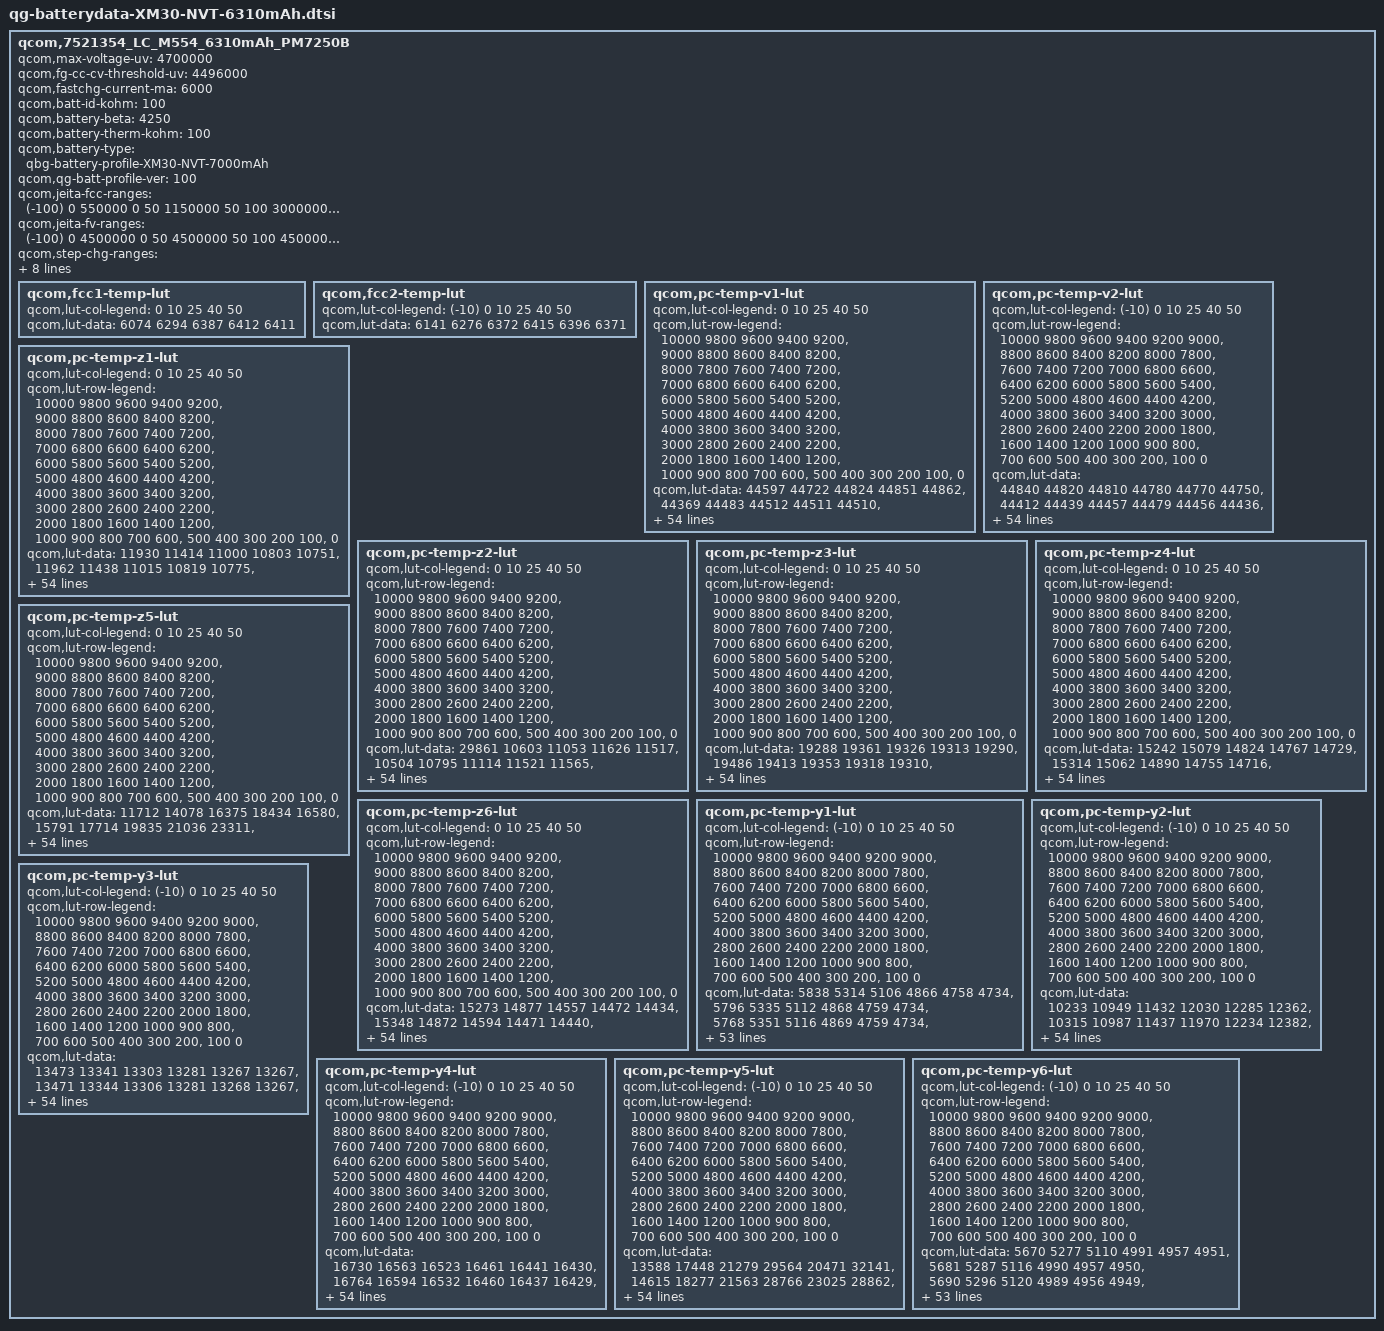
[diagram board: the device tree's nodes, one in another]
/* Copyright (c) 2018, The Linux Foundation. All rights reserved.
 *
 * This program is free software; you can redistribute it and/or modify
 * it under the terms of the GNU General Public License version 2 and
 * only version 2 as published by the Free Software Foundation.
 *
 * This program is distributed in the hope that it will be useful,
 * but WITHOUT ANY WARRANTY; without even the implied warranty of
 * MERCHANTABILITY or FITNESS FOR A PARTICULAR PURPOSE.  See the
 * GNU General Public License for more details.
 */

qcom,7521354_LC_M554_6310mAh_PM7250B {
    /* 7521354_LC_M554_6310mAh_PM7250B_averaged_MasterSlave_Dec20th2024 */
    qcom,max-voltage-uv = <4700000>;
    qcom,fg-cc-cv-threshold-uv = <4496000>;
    qcom,fastchg-current-ma = <6000>;
    qcom,batt-id-kohm = <100>;
    qcom,battery-beta = <4250>;
    qcom,battery-therm-kohm = <100>;
    qcom,battery-type = "qbg-battery-profile-XM30-NVT-7000mAh";
    qcom,qg-batt-profile-ver = <100>;

    qcom,jeita-fcc-ranges = <(-100)  0   550000
				0   50   1150000
				50  100  3000000
				100 150  3600000
				150 350  6000000
				350 450  6000000
				450 550  3000000>;
	qcom,jeita-fv-ranges = <(-100)   0   4500000
				0   50   4500000
				50  100  4500000
				100 150  4500000
				150 350  4560000
				350 480  4560000
				480 550  4100000>;
	qcom,step-chg-ranges = <3600000  4250000  6000000
				4250001  4500000  5400000
				4500001  4530000  4968000>;
	qcom,vbat-avg-based-step-chg;
	qcom,taper-fcc;

    /* COOL = 15 DegC, WARM = 45 DegC */
    qcom,jeita-soft-thresholds = <0x4621 0x20B8>;
    /* COLD = -10 DegC, HOT = 58 DegC */
    qcom,jeita-hard-thresholds = <0x6226 0x15F7>;
    /* COOL hys = 18 DegC, WARM hys = 42 DegC */
    qcom,jeita-soft-hys-thresholds = <0x4621 0x23C0>;

	qcom,jeita-soft-fcc-ua = <5400000 4500000>;
	qcom,jeita-soft-fv-uv = <4650000 4530000>;

	qcom,fcc1-temp-lut {
		qcom,lut-col-legend = <0 10 25 40 50>;
		qcom,lut-data = <6074 6294 6387 6412 6411>;
	};

	qcom,fcc2-temp-lut {
		qcom,lut-col-legend = <(-10) 0 10 25 40 50>;
		qcom,lut-data = <6141 6276 6372 6415 6396 6371>;
	};

	qcom,pc-temp-v1-lut {
		qcom,lut-col-legend = <0 10 25 40 50>;
		qcom,lut-row-legend = <10000 9800 9600 9400 9200>,
			<9000 8800 8600 8400 8200>,
			<8000 7800 7600 7400 7200>,
			<7000 6800 6600 6400 6200>,
			<6000 5800 5600 5400 5200>,
			<5000 4800 4600 4400 4200>,
			<4000 3800 3600 3400 3200>,
			<3000 2800 2600 2400 2200>,
			<2000 1800 1600 1400 1200>,
			<1000 900 800 700 600>,
			<500 400 300 200 100>,
			<0>;
		qcom,lut-data = <44597 44722 44824 44851 44862>,
			<44369 44483 44512 44511 44510>,
			<44158 44255 44286 44273 44268>,
			<43951 44041 44081 44064 44057>,
			<43737 43840 43872 43854 43848>,
			<43521 43632 43668 43651 43648>,
			<43297 43407 43449 43437 43437>,
			<43061 43172 43217 43206 43209>,
			<42820 42931 42976 42967 42974>,
			<42578 42679 42728 42720 42731>,
			<42334 42428 42474 42465 42483>,
			<42094 42178 42222 42214 42234>,
			<41860 41930 41970 41964 41984>,
			<41630 41690 41723 41718 41735>,
			<41408 41457 41484 41476 41493>,
			<41192 41230 41251 41238 41255>,
			<40984 41006 41026 41009 41025>,
			<40784 40791 40807 40788 40805>,
			<40592 40592 40599 40577 40593>,
			<40404 40407 40404 40379 40393>,
			<40229 40217 40212 40187 40200>,
			<40050 40010 39998 39979 39994>,
			<39825 39795 39765 39755 39777>,
			<39532 39568 39542 39533 39560>,
			<39285 39320 39330 39311 39334>,
			<39136 39121 39139 39105 39120>,
			<39023 38994 38989 38951 38961>,
			<38926 38891 38865 38827 38835>,
			<38846 38787 38754 38715 38720>,
			<38771 38685 38650 38608 38609>,
			<38692 38594 38556 38510 38507>,
			<38613 38512 38470 38420 38412>,
			<38542 38438 38393 38338 38325>,
			<38480 38375 38324 38264 38245>,
			<38425 38320 38266 38199 38175>,
			<38371 38269 38210 38138 38106>,
			<38321 38224 38155 38074 38031>,
			<38268 38178 38101 38009 37949>,
			<38213 38113 38032 37933 37863>,
			<38154 38023 37943 37841 37774>,
			<38073 37917 37838 37735 37673>,
			<37947 37793 37719 37615 37549>,
			<37800 37648 37578 37476 37405>,
			<37628 37470 37401 37306 37236>,
			<37475 37299 37230 37149 37085>,
			<37303 37162 37112 37044 36985>,
			<37233 37122 37083 37018 36959>,
			<37180 37090 37060 37000 36944>,
			<37137 37071 37038 36983 36927>,
			<37099 37034 36999 36939 36883>,
			<37055 36888 36784 36685 36636>,
			<36968 36451 36342 36231 36200>,
			<36638 35856 35743 35636 35622>,
			<36069 35028 34919 34815 34825>,
			<35083 33629 33627 33526 33604>,
			<30000 30000 30000 30000 30000>;
	};

	qcom,pc-temp-v2-lut {
		qcom,lut-col-legend = <(-10) 0 10 25 40 50>;
		qcom,lut-row-legend = <10000 9800 9600 9400 9200 9000>,
			<8800 8600 8400 8200 8000 7800>,
			<7600 7400 7200 7000 6800 6600>,
			<6400 6200 6000 5800 5600 5400>,
			<5200 5000 4800 4600 4400 4200>,
			<4000 3800 3600 3400 3200 3000>,
			<2800 2600 2400 2200 2000 1800>,
			<1600 1400 1200 1000 900 800>,
			<700 600 500 400 300 200>,
			<100 0>;
		qcom,lut-data = <44840 44820 44810 44780 44770 44750>,
			<44412 44439 44457 44479 44456 44436>,
			<44041 44110 44150 44209 44176 44156>,
			<43743 43847 43899 43978 43938 43916>,
			<43507 43639 43696 43781 43737 43714>,
			<43282 43435 43492 43580 43533 43509>,
			<43042 43210 43266 43360 43310 43287>,
			<42800 42978 43033 43132 43079 43059>,
			<42550 42739 42794 42894 42840 42822>,
			<42290 42491 42546 42643 42592 42574>,
			<42030 42239 42296 42390 42342 42325>,
			<41781 41985 42043 42136 42090 42076>,
			<41537 41731 41789 41882 41838 41828>,
			<41303 41484 41542 41634 41593 41584>,
			<41083 41245 41300 41390 41351 41344>,
			<40868 41014 41065 41153 41117 41111>,
			<40652 40792 40836 40924 40889 40883>,
			<40439 40579 40616 40701 40669 40663>,
			<40206 40375 40410 40487 40460 40455>,
			<39924 40187 40214 40277 40257 40256>,
			<39622 39981 40000 40062 40053 40057>,
			<39352 39712 39745 39842 39851 39858>,
			<39104 39407 39481 39615 39641 39653>,
			<38884 39153 39237 39360 39392 39413>,
			<38691 38937 39001 39102 39125 39151>,
			<38523 38748 38807 38909 38927 38948>,
			<38398 38583 38654 38766 38787 38805>,
			<38306 38439 38520 38640 38665 38683>,
			<38228 38310 38398 38520 38549 38565>,
			<38155 38189 38287 38410 38441 38457>,
			<38089 38090 38184 38308 38343 38357>,
			<38026 38017 38082 38214 38254 38265>,
			<37968 37960 37994 38126 38172 38180>,
			<37910 37905 37926 38043 38096 38104>,
			<37852 37856 37871 37963 38023 38033>,
			<37793 37807 37818 37882 37933 37942>,
			<37731 37750 37770 37801 37820 37812>,
			<37668 37689 37716 37714 37706 37678>,
			<37601 37619 37641 37617 37601 37567>,
			<37525 37538 37547 37514 37498 37462>,
			<37442 37444 37440 37412 37400 37361>,
			<37347 37328 37314 37305 37303 37264>,
			<37237 37189 37163 37176 37185 37149>,
			<37114 37035 36979 37022 37042 37010>,
			<36981 36873 36803 36880 36894 36854>,
			<36854 36726 36693 36842 36855 36814>,
			<36801 36667 36650 36815 36839 36798>,
			<36751 36621 36600 36781 36819 36781>,
			<36707 36578 36535 36729 36790 36755>,
			<36668 36532 36434 36547 36695 36694>,
			<36624 36473 36228 36110 36370 36398>,
			<36553 36318 35778 35483 35832 35915>,
			<36463 35934 35032 34639 35129 35267>,
			<36229 35171 33921 33272 34100 34366>,
			<35742 34191 32618 31723 32517 32928>,
			<35238 33076 29555 28224 27797 30082>;
	};

	qcom,pc-temp-z1-lut {
		qcom,lut-col-legend = <0 10 25 40 50>;
		qcom,lut-row-legend = <10000 9800 9600 9400 9200>,
			<9000 8800 8600 8400 8200>,
			<8000 7800 7600 7400 7200>,
			<7000 6800 6600 6400 6200>,
			<6000 5800 5600 5400 5200>,
			<5000 4800 4600 4400 4200>,
			<4000 3800 3600 3400 3200>,
			<3000 2800 2600 2400 2200>,
			<2000 1800 1600 1400 1200>,
			<1000 900 800 700 600>,
			<500 400 300 200 100>,
			<0>;
		qcom,lut-data = <11930 11414 11000 10803 10751>,
			<11962 11438 11015 10819 10775>,
			<11956 11445 11008 10817 10774>,
			<11945 11433 11000 10816 10773>,
			<11914 11384 10994 10813 10774>,
			<11848 11356 10989 10810 10775>,
			<11816 11360 10983 10809 10777>,
			<11816 11364 10977 10812 10781>,
			<11817 11362 10972 10814 10784>,
			<11813 11346 10970 10814 10784>,
			<11788 11330 10969 10813 10785>,
			<11762 11318 10967 10813 10785>,
			<11745 11308 10965 10814 10785>,
			<11731 11302 10964 10815 10786>,
			<11720 11297 10965 10816 10787>,
			<11708 11295 10965 10818 10789>,
			<11701 11302 10966 10819 10790>,
			<11704 11312 10968 10820 10793>,
			<11715 11312 10970 10821 10795>,
			<11720 11304 10972 10823 10797>,
			<11717 11299 10974 10826 10798>,
			<11713 11309 10976 10827 10799>,
			<11713 11324 10977 10828 10801>,
			<11714 11326 10979 10830 10803>,
			<11716 11323 10983 10832 10805>,
			<11732 11321 10988 10834 10807>,
			<11760 11321 10990 10837 10809>,
			<11773 11322 10992 10839 10811>,
			<11778 11324 10994 10841 10812>,
			<11780 11326 10997 10844 10815>,
			<11781 11329 11001 10847 10817>,
			<11782 11337 11004 10850 10820>,
			<11782 11347 11008 10852 10822>,
			<11770 11348 11012 10855 10824>,
			<11753 11347 11021 10857 10827>,
			<11753 11347 11028 10860 10829>,
			<11764 11361 11029 10864 10831>,
			<11777 11383 11030 10869 10832>,
			<11785 11387 11032 10873 10834>,
			<11794 11386 11037 10875 10837>,
			<11807 11386 11044 10877 10839>,
			<11833 11406 11051 10880 10842>,
			<11853 11426 11060 10883 10844>,
			<11863 11418 11068 10888 10846>,
			<11896 11432 11072 10890 10848>,
			<11893 11431 11078 10892 10849>,
			<11917 11433 11079 10894 10849>,
			<11902 11435 11089 10894 10850>,
			<11899 11443 11086 10897 10852>,
			<11932 11447 11090 10900 10854>,
			<11934 11457 11095 10905 10857>,
			<11930 11471 11102 10908 10861>,
			<11927 11518 11126 10916 10866>,
			<11948 11540 11121 10929 10875>,
			<11948 11540 11121 10929 10875>,
			<11948 11540 11121 10929 10875>;
	};

	qcom,pc-temp-z2-lut {
		qcom,lut-col-legend = <0 10 25 40 50>;
		qcom,lut-row-legend = <10000 9800 9600 9400 9200>,
			<9000 8800 8600 8400 8200>,
			<8000 7800 7600 7400 7200>,
			<7000 6800 6600 6400 6200>,
			<6000 5800 5600 5400 5200>,
			<5000 4800 4600 4400 4200>,
			<4000 3800 3600 3400 3200>,
			<3000 2800 2600 2400 2200>,
			<2000 1800 1600 1400 1200>,
			<1000 900 800 700 600>,
			<500 400 300 200 100>,
			<0>;
		qcom,lut-data = <29861 10603 11053 11626 11517>,
			<10504 10795 11114 11521 11565>,
			<10569 10912 11204 11564 11720>,
			<10635 10919 11253 11583 11811>,
			<10636 10893 11243 11573 11826>,
			<10616 10863 11216 11539 11832>,
			<10594 10828 11184 11510 11837>,
			<10570 10796 11139 11488 11845>,
			<10548 10782 11112 11474 11851>,
			<10537 10774 11119 11479 11795>,
			<10531 10771 11131 11491 11666>,
			<10528 10784 11132 11489 11626>,
			<10530 10805 11125 11431 11629>,
			<10534 10819 11120 11382 11636>,
			<10542 10830 11125 11382 11648>,
			<10568 10838 11135 11384 11669>,
			<10599 10844 11143 11393 11692>,
			<10617 10850 11150 11432 11720>,
			<10631 10859 11157 11459 11744>,
			<10645 10875 11162 11461 11758>,
			<10659 10889 11167 11461 11770>,
			<10672 10901 11178 11471 11804>,
			<10690 10910 11197 11522 11889>,
			<10714 10908 11215 11588 11946>,
			<10729 10895 11233 11683 11958>,
			<10726 10887 11246 11771 11965>,
			<10721 10891 11237 11733 11908>,
			<10717 10897 11206 11535 11676>,
			<10716 10899 11182 11430 11544>,
			<10714 10899 11165 11428 11529>,
			<10722 10900 11155 11427 11522>,
			<10746 10910 11170 11419 11536>,
			<10762 10927 11213 11404 11591>,
			<10766 10937 11228 11399 11655>,
			<10770 10946 11225 11435 11729>,
			<10777 10951 11222 11490 11807>,
			<10789 10952 11232 11532 11883>,
			<10799 10953 11261 11573 11956>,
			<10801 10961 11289 11616 11976>,
			<10803 10993 11319 11673 11965>,
			<10806 11013 11337 11710 11955>,
			<10810 11000 11326 11703 11971>,
			<10817 10988 11310 11682 11995>,
			<10834 10989 11311 11644 11942>,
			<10621 11063 11338 11659 11927>,
			<10570 11151 11379 11697 11960>,
			<10540 11133 11336 11714 11931>,
			<10480 11140 11315 11704 12032>,
			<10513 11607 11292 11672 12069>,
			<10575 12012 11288 11702 12096>,
			<10491 11716 11321 11620 11711>,
			<10383 11101 11291 11454 11623>,
			<10259 11054 11241 11372 11534>,
			<9898 10900 11179 11333 11411>,
			<9898 10900 11179 11333 11411>,
			<9898 10900 11179 11333 11411>;
	};

	qcom,pc-temp-z3-lut {
		qcom,lut-col-legend = <0 10 25 40 50>;
		qcom,lut-row-legend = <10000 9800 9600 9400 9200>,
			<9000 8800 8600 8400 8200>,
			<8000 7800 7600 7400 7200>,
			<7000 6800 6600 6400 6200>,
			<6000 5800 5600 5400 5200>,
			<5000 4800 4600 4400 4200>,
			<4000 3800 3600 3400 3200>,
			<3000 2800 2600 2400 2200>,
			<2000 1800 1600 1400 1200>,
			<1000 900 800 700 600>,
			<500 400 300 200 100>,
			<0>;
		qcom,lut-data = <19288 19361 19326 19313 19290>,
			<19486 19413 19353 19318 19310>,
			<19529 19447 19365 19323 19313>,
			<19549 19456 19371 19326 19315>,
			<19560 19460 19375 19328 19316>,
			<19567 19462 19377 19330 19317>,
			<19570 19462 19377 19331 19317>,
			<19571 19462 19377 19330 19318>,
			<19571 19462 19376 19330 19318>,
			<19571 19461 19374 19330 19317>,
			<19568 19460 19369 19329 19313>,
			<19564 19457 19367 19328 19310>,
			<19562 19453 19365 19322 19307>,
			<19560 19449 19363 19317 19306>,
			<19556 19445 19361 19316 19305>,
			<19548 19442 19359 19316 19305>,
			<19540 19441 19357 19315 19304>,
			<19535 19441 19356 19314 19301>,
			<19532 19439 19355 19313 19298>,
			<19529 19435 19355 19312 19297>,
			<19525 19433 19355 19312 19296>,
			<19523 19435 19356 19312 19296>,
			<19524 19439 19359 19314 19299>,
			<19536 19439 19360 19317 19304>,
			<19545 19436 19359 19325 19314>,
			<19543 19434 19357 19334 19324>,
			<19538 19438 19361 19335 19324>,
			<19534 19444 19373 19333 19319>,
			<19531 19445 19376 19331 19315>,
			<19528 19444 19373 19329 19312>,
			<19526 19444 19368 19327 19310>,
			<19525 19442 19365 19323 19307>,
			<19524 19439 19362 19320 19305>,
			<19520 19437 19359 19317 19302>,
			<19517 19433 19356 19315 19299>,
			<19516 19431 19355 19313 19296>,
			<19516 19431 19354 19312 19297>,
			<19516 19431 19354 19311 19299>,
			<19513 19430 19353 19311 19299>,
			<19505 19427 19352 19312 19298>,
			<19499 19424 19349 19312 19297>,
			<19493 19421 19346 19311 19298>,
			<19488 19417 19342 19309 19300>,
			<19486 19414 19342 19310 19302>,
			<19315 19397 19340 19309 19301>,
			<19261 19391 19335 19304 19295>,
			<19261 19389 19332 19302 19293>,
			<19262 19387 19332 19302 19288>,
			<19261 19314 19331 19299 19287>,
			<19261 19296 19330 19297 19288>,
			<19261 19301 19332 19306 19299>,
			<19262 19384 19334 19313 19299>,
			<19262 19385 19336 19314 19299>,
			<19271 19391 19339 19316 19303>,
			<19271 19391 19339 19316 19303>,
			<19271 19391 19339 19316 19303>;
	};

	qcom,pc-temp-z4-lut {
		qcom,lut-col-legend = <0 10 25 40 50>;
		qcom,lut-row-legend = <10000 9800 9600 9400 9200>,
			<9000 8800 8600 8400 8200>,
			<8000 7800 7600 7400 7200>,
			<7000 6800 6600 6400 6200>,
			<6000 5800 5600 5400 5200>,
			<5000 4800 4600 4400 4200>,
			<4000 3800 3600 3400 3200>,
			<3000 2800 2600 2400 2200>,
			<2000 1800 1600 1400 1200>,
			<1000 900 800 700 600>,
			<500 400 300 200 100>,
			<0>;
		qcom,lut-data = <15242 15079 14824 14767 14729>,
			<15314 15062 14890 14755 14716>,
			<15253 15030 14860 14748 14713>,
			<15162 14985 14823 14738 14707>,
			<15083 14911 14792 14726 14699>,
			<15003 14850 14763 14711 14688>,
			<14938 14811 14738 14696 14677>,
			<14892 14780 14718 14683 14666>,
			<14854 14755 14702 14671 14657>,
			<14823 14734 14689 14664 14654>,
			<14798 14718 14678 14658 14652>,
			<14776 14703 14672 14655 14650>,
			<14757 14692 14668 14653 14647>,
			<14740 14688 14664 14650 14643>,
			<14728 14685 14661 14646 14638>,
			<14717 14684 14658 14641 14633>,
			<14709 14682 14656 14637 14629>,
			<14707 14681 14654 14633 14627>,
			<14705 14679 14653 14631 14625>,
			<14704 14678 14651 14629 14623>,
			<14702 14677 14651 14628 14621>,
			<14700 14682 14656 14631 14623>,
			<14709 14692 14677 14650 14636>,
			<14758 14710 14698 14666 14648>,
			<14793 14748 14715 14674 14654>,
			<14792 14768 14727 14679 14659>,
			<14789 14752 14720 14678 14658>,
			<14783 14727 14696 14668 14654>,
			<14769 14714 14683 14659 14649>,
			<14753 14706 14677 14653 14645>,
			<14745 14703 14673 14648 14641>,
			<14738 14704 14671 14645 14637>,
			<14733 14705 14670 14643 14634>,
			<14729 14705 14670 14641 14631>,
			<14726 14703 14670 14640 14629>,
			<14724 14701 14670 14639 14628>,
			<14723 14699 14670 14641 14630>,
			<14720 14696 14670 14645 14637>,
			<14714 14693 14670 14647 14639>,
			<14705 14690 14669 14646 14637>,
			<14696 14684 14666 14644 14634>,
			<14689 14674 14659 14640 14630>,
			<14679 14662 14649 14634 14625>,
			<14664 14653 14643 14632 14624>,
			<14800 14645 14634 14628 14621>,
			<14844 14630 14625 14622 14617>,
			<14844 14627 14621 14618 14615>,
			<14841 14626 14613 14609 14609>,
			<14839 14705 14609 14604 14601>,
			<14836 14722 14611 14608 14601>,
			<14835 14718 14617 14608 14603>,
			<14835 14631 14616 14605 14605>,
			<14843 14636 14616 14606 14606>,
			<14855 14646 14617 14608 14606>,
			<14855 14646 14617 14608 14606>,
			<14855 14646 14617 14608 14606>;
	};

	qcom,pc-temp-z5-lut {
		qcom,lut-col-legend = <0 10 25 40 50>;
		qcom,lut-row-legend = <10000 9800 9600 9400 9200>,
			<9000 8800 8600 8400 8200>,
			<8000 7800 7600 7400 7200>,
			<7000 6800 6600 6400 6200>,
			<6000 5800 5600 5400 5200>,
			<5000 4800 4600 4400 4200>,
			<4000 3800 3600 3400 3200>,
			<3000 2800 2600 2400 2200>,
			<2000 1800 1600 1400 1200>,
			<1000 900 800 700 600>,
			<500 400 300 200 100>,
			<0>;
		qcom,lut-data = <11712 14078 16375 18434 16580>,
			<15791 17714 19835 21036 23311>,
			<17666 20557 21836 22549 25126>,
			<19050 22336 23249 23541 26056>,
			<20488 23529 24429 24017 26467>,
			<21820 24693 25406 24289 26687>,
			<23093 25960 26512 24749 27167>,
			<24291 27278 27772 25822 28958>,
			<25473 28763 28981 27126 30485>,
			<26769 30419 30044 28457 29975>,
			<28153 32250 31032 29786 28638>,
			<29689 34893 31985 29993 28233>,
			<31561 37217 32937 28430 28435>,
			<33653 37533 33687 27113 28825>,
			<35482 37497 34131 27864 30593>,
			<37126 37490 34512 29778 33460>,
			<38503 39581 35095 31455 34071>,
			<39432 42493 35934 32948 33424>,
			<40119 42826 37137 34460 32962>,
			<40844 42242 40123 36380 33770>,
			<41520 41910 43167 38118 35225>,
			<42395 45397 43492 38158 35870>,
			<46137 50379 43199 36492 36209>,
			<59312 49382 42503 34254 36325>,
			<65535 40896 35006 30718 33322>,
			<63796 35750 26542 27292 29023>,
			<53738 36455 27815 27155 28200>,
			<48323 38098 34913 28759 28051>,
			<45471 40818 40444 30835 28028>,
			<43921 46251 44350 33652 29330>,
			<45083 50715 47559 36841 31679>,
			<48839 53292 50213 39434 34209>,
			<51068 55040 52460 41744 37296>,
			<51456 55212 53466 43863 39673>,
			<51734 54834 53883 46233 41577>,
			<52448 54597 54080 47821 42735>,
			<53924 54726 54071 46556 42628>,
			<54777 54919 54009 42968 42018>,
			<54132 54897 53638 41639 41164>,
			<52590 54523 50489 41610 39407>,
			<50522 53950 46572 41575 38085>,
			<46733 52931 43367 40636 40792>,
			<45579 51490 41203 38974 45738>,
			<49128 50061 42115 38575 47183>,
			<21185 42100 42471 36423 44183>,
			<12075 46454 43289 32471 32227>,
			<12052 44582 41343 33254 32550>,
			<12013 42505 46640 42977 32558>,
			<11968 14507 46398 42794 40968>,
			<11896 13355 42354 32791 41763>,
			<11878 13957 35961 37451 54890>,
			<11858 33811 36967 56473 48159>,
			<11850 31275 36516 52272 42266>,
			<12626 29875 37403 49992 49162>,
			<12626 29875 37403 49992 49162>,
			<12626 29875 37403 49992 49162>;
	};

	qcom,pc-temp-z6-lut {
		qcom,lut-col-legend = <0 10 25 40 50>;
		qcom,lut-row-legend = <10000 9800 9600 9400 9200>,
			<9000 8800 8600 8400 8200>,
			<8000 7800 7600 7400 7200>,
			<7000 6800 6600 6400 6200>,
			<6000 5800 5600 5400 5200>,
			<5000 4800 4600 4400 4200>,
			<4000 3800 3600 3400 3200>,
			<3000 2800 2600 2400 2200>,
			<2000 1800 1600 1400 1200>,
			<1000 900 800 700 600>,
			<500 400 300 200 100>,
			<0>;
		qcom,lut-data = <15273 14877 14557 14472 14434>,
			<15348 14872 14594 14471 14440>,
			<15305 14859 14584 14469 14440>,
			<15239 14837 14570 14467 14439>,
			<15181 14793 14557 14463 14437>,
			<15120 14753 14543 14457 14433>,
			<15068 14727 14531 14451 14429>,
			<15028 14705 14520 14445 14425>,
			<14993 14686 14511 14440 14422>,
			<14963 14669 14503 14437 14419>,
			<14936 14656 14496 14434 14417>,
			<14912 14644 14491 14431 14414>,
			<14892 14635 14488 14427 14412>,
			<14875 14629 14486 14424 14409>,
			<14860 14624 14483 14421 14407>,
			<14844 14622 14481 14419 14405>,
			<14832 14620 14479 14417 14403>,
			<14827 14619 14478 14415 14400>,
			<14824 14618 14477 14414 14398>,
			<14823 14616 14477 14413 14397>,
			<14823 14615 14477 14413 14396>,
			<14822 14618 14479 14414 14397>,
			<14827 14625 14490 14423 14404>,
			<14854 14635 14500 14433 14413>,
			<14874 14650 14508 14442 14422>,
			<14873 14658 14514 14449 14429>,
			<14871 14654 14513 14449 14430>,
			<14868 14649 14510 14444 14426>,
			<14863 14645 14507 14440 14422>,
			<14857 14642 14503 14437 14419>,
			<14853 14641 14499 14434 14416>,
			<14851 14642 14497 14431 14413>,
			<14849 14642 14496 14428 14410>,
			<14847 14642 14495 14426 14408>,
			<14846 14641 14495 14425 14405>,
			<14847 14640 14495 14424 14404>,
			<14852 14642 14496 14425 14405>,
			<14856 14646 14498 14427 14409>,
			<14855 14646 14498 14428 14411>,
			<14854 14646 14498 14428 14410>,
			<14854 14646 14498 14428 14408>,
			<14858 14644 14495 14426 14407>,
			<14863 14642 14490 14423 14407>,
			<14868 14641 14489 14423 14407>,
			<14860 14637 14487 14422 14406>,
			<14859 14632 14482 14417 14402>,
			<14861 14631 14480 14414 14400>,
			<14863 14631 14477 14411 14395>,
			<14864 14631 14476 14407 14391>,
			<14864 14632 14478 14408 14391>,
			<14867 14638 14483 14414 14399>,
			<14874 14649 14487 14418 14401>,
			<14889 14660 14491 14420 14403>,
			<14909 14677 14497 14424 14406>,
			<14909 14677 14497 14424 14406>,
			<14909 14677 14497 14424 14406>;
	};

	qcom,pc-temp-y1-lut {
		qcom,lut-col-legend = <(-10) 0 10 25 40 50>;
		qcom,lut-row-legend = <10000 9800 9600 9400 9200 9000>,
			<8800 8600 8400 8200 8000 7800>,
			<7600 7400 7200 7000 6800 6600>,
			<6400 6200 6000 5800 5600 5400>,
			<5200 5000 4800 4600 4400 4200>,
			<4000 3800 3600 3400 3200 3000>,
			<2800 2600 2400 2200 2000 1800>,
			<1600 1400 1200 1000 900 800>,
			<700 600 500 400 300 200>,
			<100 0>;
		qcom,lut-data = <5838 5314 5106 4866 4758 4734>,
			<5796 5335 5112 4868 4759 4734>,
			<5768 5351 5116 4869 4759 4734>,
			<5750 5361 5118 4869 4759 4734>,
			<5740 5366 5119 4869 4759 4734>,
			<5738 5368 5119 4867 4758 4734>,
			<5746 5363 5117 4863 4756 4733>,
			<5763 5354 5115 4858 4755 4733>,
			<5768 5352 5114 4859 4755 4733>,
			<5755 5352 5114 4861 4755 4733>,
			<5743 5352 5113 4862 4755 4734>,
			<5748 5353 5112 4862 4754 4734>,
			<5764 5355 5110 4861 4753 4734>,
			<5772 5356 5107 4859 4753 4734>,
			<5772 5356 5102 4856 4754 4735>,
			<5772 5357 5100 4855 4755 4735>,
			<5771 5365 5108 4856 4756 4736>,
			<5763 5380 5118 4856 4756 4737>,
			<5759 5385 5118 4856 4756 4738>,
			<5784 5387 5115 4857 4757 4739>,
			<5823 5387 5114 4858 4757 4740>,
			<5830 5386 5113 4860 4758 4741>,
			<5824 5384 5113 4861 4760 4742>,
			<5815 5382 5112 4862 4761 4743>,
			<5806 5380 5110 4862 4762 4744>,
			<5797 5380 5110 4863 4763 4745>,
			<5796 5380 5116 4864 4764 4745>,
			<5817 5380 5121 4865 4765 4746>,
			<5839 5381 5121 4867 4766 4747>,
			<5847 5388 5119 4870 4766 4749>,
			<5851 5394 5118 4872 4767 4750>,
			<5852 5394 5122 4874 4769 4752>,
			<5835 5392 5129 4877 4771 4753>,
			<5815 5392 5138 4878 4773 4753>,
			<5814 5400 5149 4880 4775 4754>,
			<5823 5408 5151 4884 4777 4755>,
			<5832 5406 5145 4892 4779 4757>,
			<5841 5401 5139 4895 4780 4758>,
			<5850 5400 5149 4894 4783 4760>,
			<5849 5405 5169 4893 4787 4762>,
			<5836 5409 5173 4893 4787 4763>,
			<5823 5410 5161 4894 4785 4764>,
			<5816 5410 5164 4897 4786 4765>,
			<5812 5413 5190 4904 4788 4766>,
			<5840 5424 5159 4909 4792 4768>,
			<5883 5436 5205 4915 4793 4770>,
			<5899 5434 5178 4914 4795 4769>,
			<5873 5452 5180 4920 4796 4770>,
			<5866 5469 5196 4926 4796 4771>,
			<5927 5477 5190 4924 4799 4771>,
			<5964 5534 5204 4925 4798 4773>,
			<6006 5605 5272 4944 4800 4775>,
			<6138 5710 5360 4966 4807 4779>,
			<6110 5784 5476 4981 4813 4784>,
			<6110 5784 5476 4981 4813 4784>,
			<6110 5784 5476 4981 4813 4784>;
	};

	qcom,pc-temp-y2-lut {
		qcom,lut-col-legend = <(-10) 0 10 25 40 50>;
		qcom,lut-row-legend = <10000 9800 9600 9400 9200 9000>,
			<8800 8600 8400 8200 8000 7800>,
			<7600 7400 7200 7000 6800 6600>,
			<6400 6200 6000 5800 5600 5400>,
			<5200 5000 4800 4600 4400 4200>,
			<4000 3800 3600 3400 3200 3000>,
			<2800 2600 2400 2200 2000 1800>,
			<1600 1400 1200 1000 900 800>,
			<700 600 500 400 300 200>,
			<100 0>;
		qcom,lut-data = <10233 10949 11432 12030 12285 12362>,
			<10315 10987 11437 11970 12234 12382>,
			<10420 11036 11439 11898 12184 12394>,
			<10529 11085 11439 11826 12135 12401>,
			<10621 11124 11437 11767 12087 12403>,
			<10678 11139 11433 11734 12040 12403>,
			<10698 11136 11409 11721 11991 12362>,
			<10709 11127 11370 11711 11947 12306>,
			<10723 11115 11344 11693 11917 12303>,
			<10738 11096 11322 11668 11893 12327>,
			<10754 11080 11307 11647 11886 12340>,
			<10776 11069 11297 11628 11916 12304>,
			<10805 11061 11289 11616 11952 12249>,
			<10839 11062 11283 11623 11946 12218>,
			<10890 11082 11278 11645 11911 12195>,
			<10947 11111 11276 11654 11878 12186>,
			<10997 11151 11296 11652 11847 12184>,
			<11048 11204 11335 11651 11826 12183>,
			<11070 11260 11396 11661 11863 12175>,
			<10638 11331 11491 11693 11984 12155>,
			<9958 11373 11528 11743 12091 12153>,
			<9763 11367 11523 11859 12187 12329>,
			<9728 11355 11518 11943 12258 12518>,
			<9709 11353 11530 11920 12290 12531>,
			<9699 11366 11569 11871 12310 12528>,
			<9692 11377 11603 11860 12310 12528>,
			<9687 11373 11629 11867 12263 12560>,
			<9684 11361 11652 11880 12223 12612>,
			<9681 11347 11673 11930 12244 12679>,
			<9679 11330 11692 11997 12300 12763>,
			<9676 11300 11697 12009 12359 12802>,
			<9674 11104 11695 12005 12435 12812>,
			<9672 10684 11691 12003 12487 12823>,
			<9671 10367 11689 12014 12503 12867>,
			<9669 10134 11685 12029 12514 12938>,
			<9669 9960 11672 12027 12511 12954>,
			<9668 9851 11589 12010 12487 12905>,
			<9667 9771 11473 11991 12459 12846>,
			<9666 9729 11358 11973 12439 12806>,
			<9665 9706 11225 11959 12417 12772>,
			<9665 9692 11092 11975 12368 12785>,
			<9664 9682 10964 12020 12283 12922>,
			<9663 9675 10692 11978 12315 12916>,
			<9662 9670 10151 11881 12405 12710>,
			<9662 9666 9876 11797 12369 12708>,
			<9660 9664 9771 11779 12391 12693>,
			<9659 9662 9713 11698 12251 12552>,
			<9658 9661 9688 11660 12224 12422>,
			<9656 9659 9674 11679 12136 12412>,
			<9654 9656 9666 11631 12145 12380>,
			<9651 9653 9659 11434 12128 12175>,
			<9650 9650 9654 11250 12122 12188>,
			<9649 9649 9652 11121 11893 12211>,
			<9648 9651 9651 10795 11723 11908>,
			<9648 9651 9651 10795 11723 11908>,
			<9648 9651 9651 10795 11723 11908>;
	};

	qcom,pc-temp-y3-lut {
		qcom,lut-col-legend = <(-10) 0 10 25 40 50>;
		qcom,lut-row-legend = <10000 9800 9600 9400 9200 9000>,
			<8800 8600 8400 8200 8000 7800>,
			<7600 7400 7200 7000 6800 6600>,
			<6400 6200 6000 5800 5600 5400>,
			<5200 5000 4800 4600 4400 4200>,
			<4000 3800 3600 3400 3200 3000>,
			<2800 2600 2400 2200 2000 1800>,
			<1600 1400 1200 1000 900 800>,
			<700 600 500 400 300 200>,
			<100 0>;
		qcom,lut-data = <13473 13341 13303 13281 13267 13267>,
			<13471 13344 13306 13281 13268 13267>,
			<13469 13348 13308 13281 13269 13266>,
			<13467 13353 13310 13281 13270 13266>,
			<13466 13356 13311 13281 13271 13267>,
			<13465 13358 13313 13281 13271 13267>,
			<13464 13359 13313 13282 13270 13267>,
			<13464 13360 13314 13282 13270 13268>,
			<13464 13361 13315 13283 13270 13268>,
			<13460 13362 13316 13283 13272 13268>,
			<13455 13363 13317 13283 13272 13269>,
			<13449 13363 13317 13283 13271 13269>,
			<13443 13362 13318 13282 13270 13269>,
			<13438 13362 13318 13282 13270 13270>,
			<13434 13362 13319 13283 13271 13269>,
			<13430 13362 13319 13283 13272 13269>,
			<13425 13359 13319 13285 13273 13269>,
			<13418 13354 13319 13287 13274 13269>,
			<13412 13351 13319 13287 13274 13269>,
			<13408 13349 13316 13286 13274 13271>,
			<13404 13347 13312 13286 13274 13272>,
			<13401 13341 13309 13286 13275 13273>,
			<13399 13333 13306 13286 13276 13273>,
			<13397 13328 13303 13284 13274 13272>,
			<13388 13324 13300 13281 13270 13269>,
			<13376 13320 13298 13280 13269 13267>,
			<13373 13318 13297 13280 13269 13266>,
			<13385 13317 13296 13280 13269 13266>,
			<13404 13313 13296 13280 13269 13266>,
			<13422 13305 13295 13279 13270 13266>,
			<13442 13299 13294 13279 13270 13266>,
			<13466 13298 13292 13278 13270 13266>,
			<13495 13298 13291 13278 13270 13266>,
			<13529 13299 13291 13278 13270 13266>,
			<13566 13306 13294 13277 13270 13267>,
			<13607 13317 13295 13277 13270 13267>,
			<13654 13327 13296 13277 13269 13266>,
			<13709 13339 13298 13277 13269 13266>,
			<13770 13354 13299 13276 13268 13266>,
			<13835 13373 13301 13276 13268 13266>,
			<13906 13399 13304 13276 13268 13266>,
			<13982 13435 13309 13276 13268 13267>,
			<14063 13486 13313 13276 13269 13267>,
			<14155 13566 13316 13277 13270 13268>,
			<14266 13678 13329 13275 13269 13266>,
			<14418 13809 13353 13279 13269 13267>,
			<14525 13903 13386 13279 13269 13267>,
			<14646 14069 13432 13280 13271 13269>,
			<14846 14298 13523 13285 13274 13270>,
			<15485 14680 13693 13286 13274 13271>,
			<17412 16198 14116 13286 13273 13269>,
			<22374 22937 15608 13289 13272 13269>,
			<36844 55663 23734 13299 13274 13270>,
			<65535 65535 60994 13329 13275 13272>,
			<65535 65535 60994 13329 13275 13272>,
			<65535 65535 60994 13329 13275 13272>;
	};

	qcom,pc-temp-y4-lut {
		qcom,lut-col-legend = <(-10) 0 10 25 40 50>;
		qcom,lut-row-legend = <10000 9800 9600 9400 9200 9000>,
			<8800 8600 8400 8200 8000 7800>,
			<7600 7400 7200 7000 6800 6600>,
			<6400 6200 6000 5800 5600 5400>,
			<5200 5000 4800 4600 4400 4200>,
			<4000 3800 3600 3400 3200 3000>,
			<2800 2600 2400 2200 2000 1800>,
			<1600 1400 1200 1000 900 800>,
			<700 600 500 400 300 200>,
			<100 0>;
		qcom,lut-data = <16730 16563 16523 16461 16441 16430>,
			<16764 16594 16532 16460 16437 16429>,
			<16831 16640 16550 16459 16435 16428>,
			<16907 16689 16570 16458 16432 16427>,
			<16974 16730 16586 16458 16431 16426>,
			<17008 16752 16593 16457 16431 16425>,
			<17012 16758 16594 16457 16432 16425>,
			<17014 16762 16594 16456 16433 16424>,
			<17013 16761 16593 16456 16433 16424>,
			<16995 16750 16588 16456 16432 16425>,
			<16978 16738 16583 16456 16432 16425>,
			<16978 16729 16576 16458 16434 16425>,
			<16983 16721 16571 16461 16438 16426>,
			<16990 16721 16571 16464 16441 16428>,
			<17004 16728 16574 16468 16443 16430>,
			<17018 16740 16579 16473 16445 16433>,
			<17019 16761 16589 16478 16448 16437>,
			<17011 16792 16604 16485 16452 16442>,
			<16999 16816 16632 16498 16457 16446>,
			<16954 16837 16677 16518 16466 16450>,
			<16879 16848 16694 16534 16477 16455>,
			<16812 16802 16668 16551 16497 16470>,
			<16743 16702 16627 16560 16511 16483>,
			<16692 16637 16580 16529 16493 16473>,
			<16663 16597 16525 16466 16448 16440>,
			<16642 16567 16499 16448 16433 16427>,
			<16636 16542 16491 16446 16432 16428>,
			<16634 16523 16487 16445 16432 16428>,
			<16634 16513 16484 16446 16432 16429>,
			<16635 16508 16482 16448 16434 16431>,
			<16639 16505 16479 16450 16436 16433>,
			<16642 16511 16472 16454 16441 16436>,
			<16643 16524 16466 16457 16446 16440>,
			<16645 16534 16466 16460 16453 16446>,
			<16649 16541 16466 16463 16459 16452>,
			<16659 16548 16467 16462 16458 16453>,
			<16668 16558 16480 16457 16444 16440>,
			<16673 16571 16494 16450 16432 16427>,
			<16678 16582 16498 16440 16429 16425>,
			<16683 16593 16500 16431 16426 16424>,
			<16690 16601 16504 16432 16426 16424>,
			<16695 16604 16510 16437 16428 16425>,
			<16694 16606 16518 16443 16429 16425>,
			<16694 16610 16532 16446 16429 16426>,
			<16694 16613 16547 16440 16421 16417>,
			<16692 16613 16556 16449 16426 16420>,
			<16683 16619 16576 16458 16431 16424>,
			<16685 16630 16604 16475 16436 16428>,
			<16694 16645 16652 16505 16455 16447>,
			<16735 16670 16719 16503 16477 16495>,
			<16933 16816 16810 16496 16449 16441>,
			<17539 17899 16996 16510 16438 16433>,
			<19985 25180 21278 16553 16449 16436>,
			<20068 65535 65535 16661 16467 16451>,
			<20068 65535 65535 16661 16467 16451>,
			<20068 65535 65535 16661 16467 16451>;
	};

	qcom,pc-temp-y5-lut {
		qcom,lut-col-legend = <(-10) 0 10 25 40 50>;
		qcom,lut-row-legend = <10000 9800 9600 9400 9200 9000>,
			<8800 8600 8400 8200 8000 7800>,
			<7600 7400 7200 7000 6800 6600>,
			<6400 6200 6000 5800 5600 5400>,
			<5200 5000 4800 4600 4400 4200>,
			<4000 3800 3600 3400 3200 3000>,
			<2800 2600 2400 2200 2000 1800>,
			<1600 1400 1200 1000 900 800>,
			<700 600 500 400 300 200>,
			<100 0>;
		qcom,lut-data = <13588 17448 21279 29564 20471 32141>,
			<14615 18277 21563 28766 23025 28862>,
			<15594 19071 22040 27597 24560 26652>,
			<16516 19807 22562 26356 25337 25317>,
			<17366 20465 22978 25343 25615 24664>,
			<18134 21024 23137 24859 25638 24501>,
			<18925 21521 23105 24755 24051 25423>,
			<19641 21934 23059 24675 21933 26705>,
			<19835 22162 23135 24343 21936 26625>,
			<19778 22320 23475 23456 23030 25443>,
			<19674 22389 23654 22467 23532 24599>,
			<19467 22077 23351 21340 21511 24388>,
			<19120 21388 22779 20286 19020 24210>,
			<18983 20766 22173 19596 18545 23598>,
			<19417 20144 21425 19052 18383 22132>,
			<20196 19613 20647 18911 18354 20663>,
			<21126 19185 19725 19174 18664 19119>,
			<22421 18849 18959 19430 18991 17977>,
			<23077 19079 18691 18986 18703 18103>,
			<22062 21326 18538 17914 17876 18945>,
			<20250 23363 18599 17784 17668 19819>,
			<19184 23925 21206 20166 19116 20519>,
			<18629 24268 24175 23195 20860 21396>,
			<17954 24331 24790 25545 21678 23460>,
			<16128 24294 25060 27716 22270 26806>,
			<13662 24265 25118 29174 23056 27938>,
			<12934 24642 24949 30327 24324 26685>,
			<12958 25408 24784 30865 25183 25165>,
			<12981 25114 25030 30412 25261 24517>,
			<12952 20221 25657 29430 25293 24093>,
			<12872 15632 25732 28545 25365 23540>,
			<12844 14703 24012 27640 25528 22615>,
			<13049 14194 22452 26902 25633 21974>,
			<13318 14147 23605 26311 25206 22086>,
			<13412 14795 26289 25897 24473 22545>,
			<13449 15372 27078 26380 24636 23448>,
			<13510 15317 26784 28510 26408 26378>,
			<13808 15142 26354 29605 27556 28737>,
			<14215 15080 25845 29461 26953 28942>,
			<14398 15078 25248 29121 26050 29024>,
			<14495 15076 24866 27820 25952 29298>,
			<14539 14826 24673 25376 26268 30290>,
			<14426 14315 23179 25760 27063 31847>,
			<14132 14160 17456 25964 28732 33797>,
			<13455 14091 15432 22958 31100 33642>,
			<13143 13750 14980 26655 25334 28003>,
			<13277 13221 15078 23312 23044 24463>,
			<12987 13387 14907 21898 24054 28776>,
			<12633 13367 14805 23489 27757 28940>,
			<12316 13181 14491 24751 25567 24570>,
			<11305 12299 14253 24800 25766 25075>,
			<10057 10089 12632 24107 29185 29873>,
			<9619 9238 9390 23355 30153 28669>,
			<23962 8858 8840 22612 27610 29329>,
			<23962 8858 8840 22612 27610 29329>,
			<23962 8858 8840 22612 27610 29329>;
	};

	qcom,pc-temp-y6-lut {
		qcom,lut-col-legend = <(-10) 0 10 25 40 50>;
		qcom,lut-row-legend = <10000 9800 9600 9400 9200 9000>,
			<8800 8600 8400 8200 8000 7800>,
			<7600 7400 7200 7000 6800 6600>,
			<6400 6200 6000 5800 5600 5400>,
			<5200 5000 4800 4600 4400 4200>,
			<4000 3800 3600 3400 3200 3000>,
			<2800 2600 2400 2200 2000 1800>,
			<1600 1400 1200 1000 900 800>,
			<700 600 500 400 300 200>,
			<100 0>;
		qcom,lut-data = <5670 5277 5110 4991 4957 4951>,
			<5681 5287 5116 4990 4957 4950>,
			<5690 5296 5120 4989 4956 4949>,
			<5698 5303 5122 4988 4956 4949>,
			<5703 5308 5123 4987 4956 4949>,
			<5705 5310 5123 4987 4956 4949>,
			<5704 5309 5122 4987 4956 4949>,
			<5700 5306 5119 4987 4956 4949>,
			<5695 5303 5117 4987 4956 4950>,
			<5683 5297 5114 4987 4957 4950>,
			<5671 5292 5112 4986 4957 4950>,
			<5665 5286 5108 4987 4958 4951>,
			<5661 5282 5105 4987 4958 4951>,
			<5660 5281 5105 4988 4959 4952>,
			<5665 5282 5105 4989 4960 4953>,
			<5671 5283 5105 4991 4961 4954>,
			<5671 5287 5107 4993 4962 4954>,
			<5670 5293 5111 4997 4964 4956>,
			<5668 5297 5118 5001 4966 4957>,
			<5652 5302 5127 5006 4969 4960>,
			<5626 5305 5131 5010 4972 4962>,
			<5607 5291 5122 5015 4978 4967>,
			<5589 5260 5109 5017 4983 4971>,
			<5579 5241 5093 5007 4976 4967>,
			<5577 5230 5076 4987 4961 4956>,
			<5576 5223 5069 4982 4956 4951>,
			<5578 5219 5067 4981 4956 4951>,
			<5598 5217 5067 4981 4956 4950>,
			<5626 5217 5067 4981 4956 4951>,
			<5650 5219 5068 4982 4957 4951>,
			<5676 5222 5068 4983 4958 4952>,
			<5704 5230 5068 4984 4959 4953>,
			<5733 5244 5067 4985 4961 4954>,
			<5765 5261 5069 4986 4963 4956>,
			<5802 5281 5074 4987 4965 4958>,
			<5843 5304 5081 4987 4965 4959>,
			<5887 5330 5090 4986 4961 4955>,
			<5934 5360 5100 4984 4957 4952>,
			<5984 5395 5110 4982 4956 4951>,
			<6039 5439 5121 4980 4955 4951>,
			<6100 5489 5136 4980 4955 4951>,
			<6165 5542 5158 4982 4956 4952>,
			<6233 5602 5186 4986 4957 4953>,
			<6311 5684 5222 4988 4958 4953>,
			<6415 5788 5270 4986 4955 4949>,
			<6553 5909 5328 4992 4957 4951>,
			<6641 5993 5387 4996 4959 4953>,
			<6745 6135 5469 5003 4962 4955>,
			<6923 6332 5593 5017 4969 4962>,
			<7482 6663 5784 5018 4976 4976>,
			<9076 7922 6177 5018 4967 4959>,
			<12869 13107 7431 5029 4964 4957>,
			<23401 35587 14561 5058 4969 4959>,
			<60209 65535 53904 5130 4976 4965>,
			<60209 65535 53904 5130 4976 4965>,
			<60209 65535 53904 5130 4976 4965>;
	};

};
